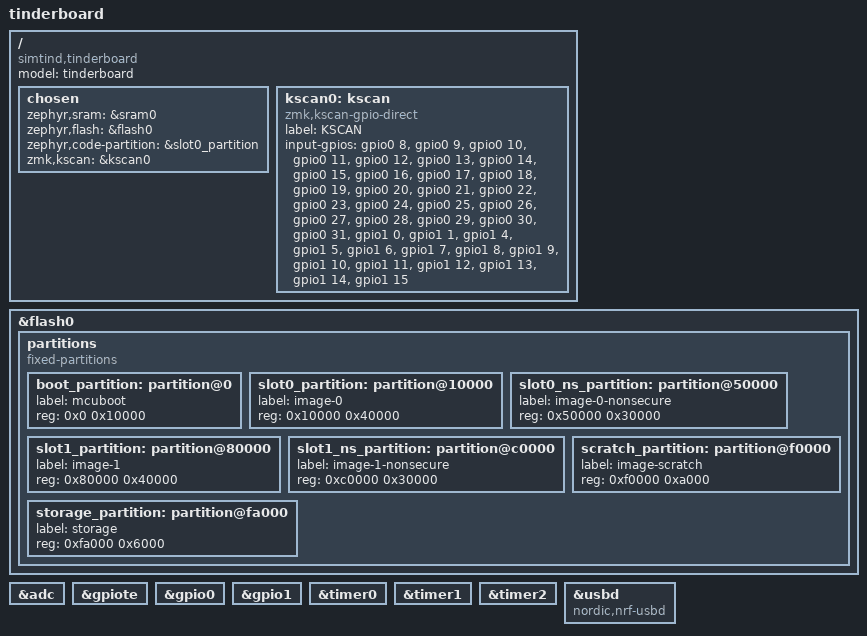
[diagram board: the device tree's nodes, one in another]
// Copyright (c) 2022 Nordic Semiconductor ASA
// SPDX-License-Identifier: Apache-2.0

/dts-v1/;
#include <nordic/nrf5340_cpuapp_qkaa.dtsi>
#include <dt-bindings/zmk/matrix_transform.h>

/ {
	model = "tinderboard";
	compatible = "simtind,tinderboard";

	chosen {
		zephyr,sram = &sram0;
		zephyr,flash = &flash0;
		zephyr,code-partition = &slot0_partition;
		zmk,kscan = &kscan0;
	};

	kscan0: kscan {
		compatible="zmk,kscan-gpio-direct";
		label = "KSCAN";
		input-gpios =
			<&gpio0 8  (GPIO_ACTIVE_HIGH | GPIO_PULL_DOWN)>,
			<&gpio0 9  (GPIO_ACTIVE_HIGH | GPIO_PULL_DOWN)>,
			<&gpio0 10 (GPIO_ACTIVE_HIGH | GPIO_PULL_DOWN)>,
			<&gpio0 11 (GPIO_ACTIVE_HIGH | GPIO_PULL_DOWN)>,
			<&gpio0 12 (GPIO_ACTIVE_HIGH | GPIO_PULL_DOWN)>,
			<&gpio0 13 (GPIO_ACTIVE_HIGH | GPIO_PULL_DOWN)>,
			<&gpio0 14 (GPIO_ACTIVE_HIGH | GPIO_PULL_DOWN)>,
			<&gpio0 15 (GPIO_ACTIVE_HIGH | GPIO_PULL_DOWN)>,
			<&gpio0 16 (GPIO_ACTIVE_HIGH | GPIO_PULL_DOWN)>,
			<&gpio0 17 (GPIO_ACTIVE_HIGH | GPIO_PULL_DOWN)>,
			<&gpio0 18 (GPIO_ACTIVE_HIGH | GPIO_PULL_DOWN)>,
			<&gpio0 19 (GPIO_ACTIVE_HIGH | GPIO_PULL_DOWN)>,
			<&gpio0 20 (GPIO_ACTIVE_HIGH | GPIO_PULL_DOWN)>,
			<&gpio0 21 (GPIO_ACTIVE_HIGH | GPIO_PULL_DOWN)>,
			<&gpio0 22 (GPIO_ACTIVE_HIGH | GPIO_PULL_DOWN)>,
			<&gpio0 23 (GPIO_ACTIVE_HIGH | GPIO_PULL_DOWN)>,
			<&gpio0 24 (GPIO_ACTIVE_HIGH | GPIO_PULL_DOWN)>,
			<&gpio0 25 (GPIO_ACTIVE_HIGH | GPIO_PULL_DOWN)>,
			<&gpio0 26 (GPIO_ACTIVE_HIGH | GPIO_PULL_DOWN)>,
			<&gpio0 27 (GPIO_ACTIVE_HIGH | GPIO_PULL_DOWN)>,
			<&gpio0 28 (GPIO_ACTIVE_HIGH | GPIO_PULL_DOWN)>,
			<&gpio0 29 (GPIO_ACTIVE_HIGH | GPIO_PULL_DOWN)>,
			<&gpio0 30 (GPIO_ACTIVE_HIGH | GPIO_PULL_DOWN)>,
			<&gpio0 31 (GPIO_ACTIVE_HIGH | GPIO_PULL_DOWN)>,
			<&gpio1 0  (GPIO_ACTIVE_HIGH | GPIO_PULL_DOWN)>,
			<&gpio1 1  (GPIO_ACTIVE_HIGH | GPIO_PULL_DOWN)>,
			<&gpio1 4  (GPIO_ACTIVE_HIGH | GPIO_PULL_DOWN)>,
			<&gpio1 5  (GPIO_ACTIVE_HIGH | GPIO_PULL_DOWN)>,
			<&gpio1 6  (GPIO_ACTIVE_HIGH | GPIO_PULL_DOWN)>,
			<&gpio1 7  (GPIO_ACTIVE_HIGH | GPIO_PULL_DOWN)>,
			<&gpio1 8  (GPIO_ACTIVE_HIGH | GPIO_PULL_DOWN)>,
			<&gpio1 9  (GPIO_ACTIVE_HIGH | GPIO_PULL_DOWN)>,
			<&gpio1 10 (GPIO_ACTIVE_HIGH | GPIO_PULL_DOWN)>,
			<&gpio1 11 (GPIO_ACTIVE_HIGH | GPIO_PULL_DOWN)>,
			<&gpio1 12 (GPIO_ACTIVE_HIGH | GPIO_PULL_DOWN)>,
			<&gpio1 13 (GPIO_ACTIVE_HIGH | GPIO_PULL_DOWN)>,
			<&gpio1 14 (GPIO_ACTIVE_HIGH | GPIO_PULL_DOWN)>,
			<&gpio1 15 (GPIO_ACTIVE_HIGH | GPIO_PULL_DOWN)>
			;
	};
};

&flash0 {
	partitions {
		compatible = "fixed-partitions";
		#address-cells = <1>;
		#size-cells = <1>;

		boot_partition: partition@0 {
			label = "mcuboot";
			reg = <0x0 0x10000>;
		};
		slot0_partition: partition@10000 {
			label = "image-0";
			reg = <0x10000 0x40000>;
		};
		slot0_ns_partition: partition@50000 {
			label = "image-0-nonsecure";
			reg = <0x50000 0x30000>;
		};
		slot1_partition: partition@80000 {
			label = "image-1";
			reg = <0x80000 0x40000>;
		};
		slot1_ns_partition: partition@c0000 {
			label = "image-1-nonsecure";
			reg = <0xc0000 0x30000>;
		};
		scratch_partition: partition@f0000 {
			label = "image-scratch";
			reg = <0xf0000 0xa000>;
		};
		storage_partition: partition@fa000 {
			label = "storage";
			reg = <0xfa000 0x6000>;
		};
	};
};

&adc {
	status = "okay";
};

&gpiote {
	status = "okay";
};

&gpio0 {
	status = "okay";
};

&gpio1 {
	status = "okay";
};

&timer0 {
	status = "okay";
};

&timer1 {
	status = "okay";
};

&timer2 {
	status = "okay";
};

zephyr_udc0: &usbd {
	compatible = "nordic,nrf-usbd";
	status = "okay";
};

#include "tinderboard_shared_sram_planning_conf.dts"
